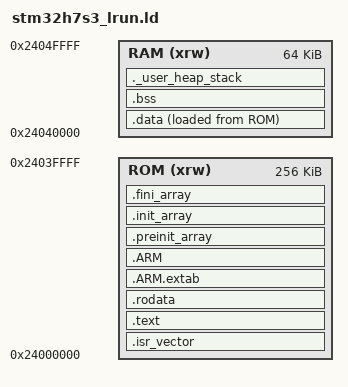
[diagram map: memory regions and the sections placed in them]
/*
 * STM32H7S3L8 linker script -- SRAM-load (no XSPI flash bring-up).
 *
 * The H7S3 has only 64 KB of internal user flash (FSBL/CCB use only) so
 * main code runs from external XSPI or, for this BARE bench, directly
 * from AXI SRAM after a debugger load. ST-LINK / CubeProgrammer can
 * write the image at 0x24000000 and set PC to Reset_Handler.
 *
 * Memory layout (per RM0477):
 *   AXISRAM1 + AXISRAM2 contiguous: 0x24000000, 320 KB
 *   DTCM:                           0x20000000, 64 KB (cpu-coupled)
 *   ITCM:                           0x00000000, 64 KB
 *   BKPSRAM:                        0x38800000, 4 KB
 *
 * We keep code + rodata in the lower part of AXI SRAM ("ROM" region) and
 * data + bss + heap + stack in the upper part ("RAM" region). This
 * matches the N657 lrun pattern.
 */

ENTRY(Reset_Handler)

/* Highest address of the user mode stack */
_estack = ORIGIN(RAM) + LENGTH(RAM);
_sstack = _estack - _Min_Stack_Size;

_Min_Heap_Size  = 0x4000;  /* 16K heap  */
_Min_Stack_Size = DEFINED(_stack_size) ? _stack_size : 0x4000;  /* 16K stack */
_heap_limit = _estack - _Min_Stack_Size;

MEMORY
{
  ROM (xrw) : ORIGIN = 0x24000000, LENGTH = 256K
  RAM (xrw) : ORIGIN = 0x24040000, LENGTH = 64K
}

SECTIONS
{
  .isr_vector :
  {
    . = ALIGN(4);
    KEEP(*(.isr_vector))
    . = ALIGN(4);
  } >ROM

  .text :
  {
    . = ALIGN(4);
    *(.text)
    *(.text*)
    *(.glue_7)
    *(.glue_7t)
    *(.eh_frame)
    *(.RamFunc)
    *(.RamFunc*)

    KEEP (*(.init))
    KEEP (*(.fini))

    . = ALIGN(4);
    _etext = .;
  } >ROM

  .rodata :
  {
    . = ALIGN(4);
    *(.rodata)
    *(.rodata*)
    . = ALIGN(4);
  } >ROM

  .ARM.extab :
  {
    . = ALIGN(4);
    *(.ARM.extab* .gnu.linkonce.armextab.*)
    . = ALIGN(4);
  } >ROM

  .ARM :
  {
    . = ALIGN(4);
    __exidx_start = .;
    *(.ARM.exidx*)
    __exidx_end = .;
    . = ALIGN(4);
  } >ROM

  .preinit_array :
  {
    . = ALIGN(4);
    PROVIDE_HIDDEN (__preinit_array_start = .);
    KEEP (*(.preinit_array*))
    PROVIDE_HIDDEN (__preinit_array_end = .);
    . = ALIGN(4);
  } >ROM

  .init_array :
  {
    . = ALIGN(4);
    PROVIDE_HIDDEN (__init_array_start = .);
    KEEP (*(SORT(.init_array.*)))
    KEEP (*(.init_array*))
    PROVIDE_HIDDEN (__init_array_end = .);
    . = ALIGN(4);
  } >ROM

  .fini_array :
  {
    . = ALIGN(4);
    PROVIDE_HIDDEN (__fini_array_start = .);
    KEEP (*(SORT(.fini_array.*)))
    KEEP (*(.fini_array*))
    PROVIDE_HIDDEN (__fini_array_end = .);
    . = ALIGN(4);
  } >ROM

  _sidata = LOADADDR(.data);

  .data :
  {
    . = ALIGN(4);
    _sdata = .;
    *(.data)
    *(.data*)
    . = ALIGN(4);
    _edata = .;
  } >RAM AT> ROM

  . = ALIGN(4);
  .bss :
  {
    _sbss = .;
    __bss_start__ = _sbss;
    *(.bss)
    *(.bss*)
    *(COMMON)
    . = ALIGN(4);
    _ebss = .;
    __bss_end__ = _ebss;
  } >RAM

  ._user_heap_stack :
  {
    . = ALIGN(8);
    PROVIDE ( end = . );
    PROVIDE ( _end = . );
    . = . + _Min_Heap_Size;
    . = . + _Min_Stack_Size;
    . = ALIGN(8);
  } >RAM

  /DISCARD/ :
  {
    libc.a ( * )
    libm.a ( * )
    libgcc.a ( * )
  }

  .ARM.attributes 0 : { *(.ARM.attributes) }
}
